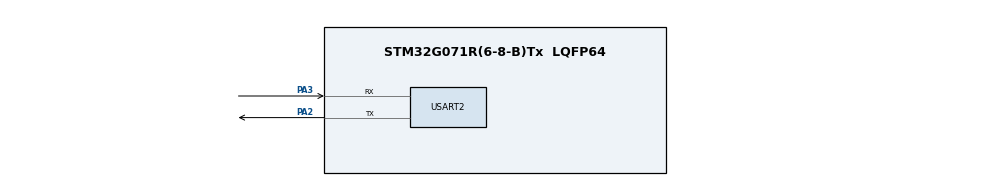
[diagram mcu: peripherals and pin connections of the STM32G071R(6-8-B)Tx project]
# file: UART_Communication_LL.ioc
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Mcu.Family=STM32G0
Mcu.Name=STM32G071R(6-8-B)Tx
Mcu.Package=LQFP64
PA13.Mode=Serial_Wire
PA13.Signal=SYS_SWDIO
PA14-BOOT0.Mode=Serial_Wire
PA14-BOOT0.Signal=SYS_SWCLK
PA2.Mode=Asynchronous
PA2.Signal=USART2_TX
PA3.Mode=Asynchronous
PA3.Signal=USART2_RX
ProjectManager.HeapSize=0x200
ProjectManager.StackSize=0x400
ProjectManager.TargetToolchain=STM32CubeIDE
RCC.AHBFreq_Value=16000000
RCC.CortexFreq_Value=16000000
RCC.EXTERNAL_CLOCK_VALUE=48000
RCC.HCLKFreq_Value=16000000
RCC.HSE_VALUE=8000000
RCC.HSI_VALUE=16000000
RCC.LSE_VALUE=32768
RCC.SYSCLKFreq_VALUE=16000000
RCC.VCOOutputFreq_Value=128000000
USART2.VirtualMode-Asynchronous=VM_ASYNC
board=custom

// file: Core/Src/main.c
/* USER CODE BEGIN Header */
/**
  ******************************************************************************
  * @file           : main.c
  * @brief          : Main program body
  ******************************************************************************
  * @attention
  *
  * Copyright (c) 2024 STMicroelectronics.
  * All rights reserved.
  *
  * This software is licensed under terms that can be found in the LICENSE file
  * in the root directory of this software component.
  * If no LICENSE file comes with this software, it is provided AS-IS.
  *
  ******************************************************************************
  */
/* USER CODE END Header */
#include "main.h"
#include "usart.h"
#include "gpio.h"

/* USER CODE BEGIN Includes */
#include <stdio.h>
//

/* USER CODE END Includes */

void SystemClock_Config(void);

int main(void)
{

  /* USER CODE BEGIN 1 */
void PrintOutBuffer(uint8_t *OutputBuffer)
{
	uint32_t BufferIndex;

	//The position of the NULL character (0) marks the end of the character array.
	BufferIndex =0;
	while(*(OutputBuffer+ BufferIndex)!=0){

		//wait for the transmit data register to be empty
		while(!LL_USART_IsActiveFlag_TXE_TXFNF(USART2));

		//empty -> transmit
		LL_USART_TransmitData8(USART2, (uint8_t)(*(OutputBuffer +BufferIndex)));
		//By using USART2, send 1bite(8bit) of

		//increment the outputbuffer index
		BufferIndex++;

		//clear TC flag
		if(*(OutputBuffer+BufferIndex)==0) {LL_USART_ClearFlag_TC(USART2);}
		//if next turn's value is 0, TC clear(it means the transmission ends)
		//prepare next transmission

	}

	//Wait for transmission to complete
	while (!LL_USART_IsActiveFlag_TC(USART2));

}

uint8_t GetUserInput(void)
{
	uint8_t ReturnValue;
	while (!LL_USART_IsActiveFlag_RXNE_RXFNE(USART2));

	ReturnValue = LL_USART_ReceiveData8(USART2);

	return ReturnValue;

}

  /* USER CODE END 1 */

  /* MCU Configuration--------------------------------------------------------*/

  /* Reset of all peripherals, Initializes the Flash interface and the Systick. */
  LL_APB2_GRP1_EnableClock(LL_APB2_GRP1_PERIPH_SYSCFG);
  LL_APB1_GRP1_EnableClock(LL_APB1_GRP1_PERIPH_PWR);

  /* SysTick_IRQn interrupt configuration */
  NVIC_SetPriority(SysTick_IRQn, 3);

  /* Configure the system clock */
  SystemClock_Config();

  /* Initialize all configured peripherals */
  MX_GPIO_Init();
  MX_USART2_UART_Init();
  /* USER CODE BEGIN 2 */

	  uint8_t OutputBuffer[200];
	  uint8_t ReceiveCharacter;
	  int i = 0;

  /* USER CODE END 2 */

  /* Infinite loop */
  /* USER CODE BEGIN WHILE */
  while (1)
  {

	 sprintf((char *) OutputBuffer, "Hello, world! %d\r\n",i++);
	 //save the char in outputbuffer
	 PrintOutBuffer(OutputBuffer);

	 //for (volatile int delay = 0; delay < 10; delay++);

	 sprintf((char *) OutputBuffer, "Press any key to continue...\r\n");
	 PrintOutBuffer(OutputBuffer);

	 //wait for a character.
	 ReceiveCharacter = GetUserInput();

	 //Echo character entered.
	 sprintf((char *) OutputBuffer, "You entered: %c\r\n",ReceiveCharacter);
	 PrintOutBuffer(OutputBuffer);

    /* USER CODE END WHILE */

  }
}

void SystemClock_Config(void)
{
  /* HSI configuration and activation */
  LL_RCC_HSI_Enable();
  while(LL_RCC_HSI_IsReady() != 1)
  {
  }

  /* Set AHB prescaler*/
  LL_RCC_SetAHBPrescaler(LL_RCC_SYSCLK_DIV_1);

  /* Sysclk activation on the HSI */
  LL_RCC_SetSysClkSource(LL_RCC_SYS_CLKSOURCE_HSI);
  while(LL_RCC_GetSysClkSource() != LL_RCC_SYS_CLKSOURCE_STATUS_HSI)
  {
  }

  /* Set APB1 prescaler*/
  LL_RCC_SetAPB1Prescaler(LL_RCC_APB1_DIV_1);
  LL_Init1msTick(16000000);
  /* Update CMSIS variable (which can be updated also through SystemCoreClockUpdate function) */
  LL_SetSystemCoreClock(16000000);
}

void Error_Handler(void)
{
  __disable_irq();
  while (1)
  {
  }
}
